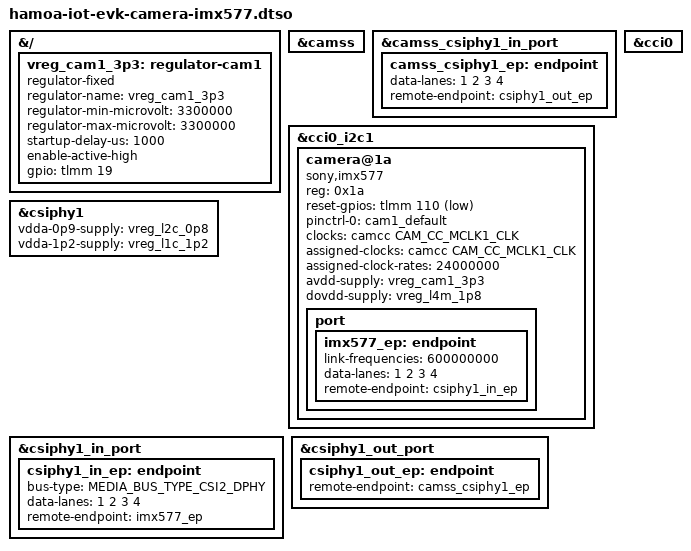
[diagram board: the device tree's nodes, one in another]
// SPDX-License-Identifier: BSD-3-Clause
/*
 * Copyright (c) Qualcomm Technologies, Inc. and/or its subsidiaries.
 */

/dts-v1/;
/plugin/;

#include <dt-bindings/clock/qcom,x1e80100-camcc.h>
#include <dt-bindings/gpio/gpio.h>
#include <dt-bindings/media/video-interfaces.h>

&{/} {
	vreg_cam1_3p3: regulator-cam1 {
		compatible = "regulator-fixed";
		regulator-name = "vreg_cam1_3p3";
		regulator-min-microvolt = <3300000>;
		regulator-max-microvolt = <3300000>;
		startup-delay-us = <1000>;
		enable-active-high;
		gpio = <&tlmm 19 GPIO_ACTIVE_HIGH>;
	};
};

&camss {
	status = "okay";
};

&camss_csiphy1_in_port {
	camss_csiphy1_ep: endpoint {
		data-lanes = <1 2 3 4>;
		remote-endpoint = <&csiphy1_out_ep>;
	};
};

&cci0 {
	status = "okay";
};

&cci0_i2c1 {
	#address-cells = <1>;
	#size-cells = <0>;

	camera@1a {
		compatible = "sony,imx577";
		reg = <0x1a>;

		reset-gpios = <&tlmm 110 GPIO_ACTIVE_LOW>;
		pinctrl-0 = <&cam1_default>;
		pinctrl-names = "default";

		clocks = <&camcc CAM_CC_MCLK1_CLK>;
		assigned-clocks = <&camcc CAM_CC_MCLK1_CLK>;
		assigned-clock-rates = <24000000>;

		avdd-supply = <&vreg_cam1_3p3>;
		dovdd-supply = <&vreg_l4m_1p8>;

		port {
			imx577_ep: endpoint {
				link-frequencies = /bits/ 64 <600000000>;
				data-lanes = <1 2 3 4>;
				remote-endpoint = <&csiphy1_in_ep>;
			};
		};
	};
};

&csiphy1 {
	vdda-0p9-supply = <&vreg_l2c_0p8>;
	vdda-1p2-supply = <&vreg_l1c_1p2>;

	status = "okay";
};

&csiphy1_in_port {
	csiphy1_in_ep: endpoint {
		bus-type = <MEDIA_BUS_TYPE_CSI2_DPHY>;
		data-lanes = <1 2 3 4>;
		remote-endpoint = <&imx577_ep>;
	};
};

&csiphy1_out_port {
	csiphy1_out_ep: endpoint {
		remote-endpoint = <&camss_csiphy1_ep>;
	};
};
